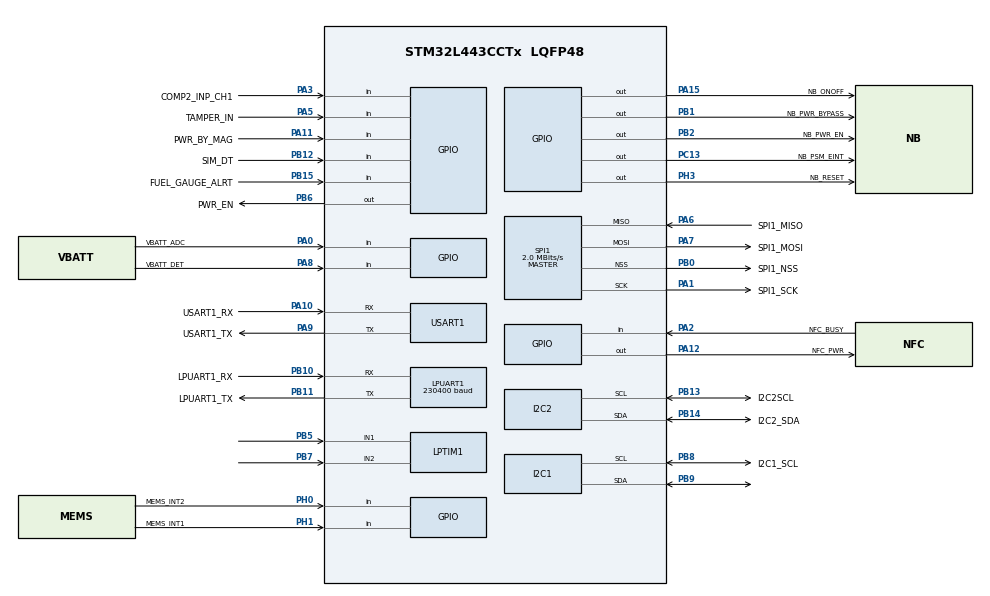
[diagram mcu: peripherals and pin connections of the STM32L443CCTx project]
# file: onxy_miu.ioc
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I2C1.Timing=0x00100D14
I2C2.Timing=0x00100D14
LPUART1.BaudRate=230400
LPUART1.WordLength=UART_WORDLENGTH_8B
Mcu.Family=STM32L4
Mcu.Name=STM32L443CCTx
Mcu.Package=LQFP48
NVIC.LPTIM1_IRQn=true\:0\:0\:false\:false\:true\:true\:true\:true
NVIC.PriorityGroup=NVIC_PRIORITYGROUP_4
NVIC.RTC_Alarm_IRQn=true\:0\:0\:false\:false\:true\:true\:true\:true
NVIC.WWDG_IRQn=true\:0\:0\:false\:false\:true\:true\:true\:true
PA0.GPIO_Label=VBATT_ADC
PA0.Signal=GPIO_Input
PA1.GPIO_Label=SPI1_SCK
PA1.Mode=Full_Duplex_Master
PA1.Signal=SPI1_SCK
PA10.GPIO_Label=USART1_RX
PA10.Mode=Asynchronous
PA10.Signal=USART1_RX
PA11.GPIO_Label=PWR_BY_MAG
PA11.Signal=GPIO_Input
PA12.GPIO_Label=NFC_PWR
PA12.Signal=GPIO_Output
PA13\ (JTMS-SWDIO).Mode=Serial_Wire
PA13\ (JTMS-SWDIO).Signal=SYS_JTMS-SWDIO
PA14\ (JTCK-SWCLK).Mode=Serial_Wire
PA14\ (JTCK-SWCLK).Signal=SYS_JTCK-SWCLK
PA15\ (JTDI).GPIO_Label=NB_ONOFF
PA15\ (JTDI).Signal=GPIO_Output
PA2.GPIO_Label=NFC_BUSY
PA2.Signal=GPIO_Input
PA3.GPIO_Label=COMP2_INP_CH1
PA3.Signal=GPIO_Input
PA5.GPIO_Label=TAMPER_IN
PA5.Signal=GPIO_Input
PA6.GPIO_Label=SPI1_MISO
PA6.Mode=Full_Duplex_Master
PA6.Signal=SPI1_MISO
PA7.GPIO_Label=SPI1_MOSI
PA7.Mode=Full_Duplex_Master
PA7.Signal=SPI1_MOSI
PA8.GPIO_Label=VBATT_DET
PA8.Signal=GPIO_Input
PA9.GPIO_Label=USART1_TX
PA9.Mode=Asynchronous
PA9.Signal=USART1_TX
PB0.GPIO_Label=SPI1_NSS
PB0.Mode=NSS_Signal_Hard_Output
PB0.Signal=SPI1_NSS
PB1.GPIO_Label=NB_PWR_BYPASS
PB1.Signal=GPIO_Output
PB10.GPIO_Label=LPUART1_RX
PB10.Mode=Asynchronous
PB10.Signal=LPUART1_RX
PB11.GPIO_Label=LPUART1_TX
PB11.Mode=Asynchronous
PB11.Signal=LPUART1_TX
PB12.GPIO_Label=SIM_DT
PB12.Signal=GPIO_Input
PB13.GPIO_Label=I2C2SCL
PB13.Mode=I2C
PB13.Signal=I2C2_SCL
PB14.GPIO_Label=I2C2_SDA
PB14.Mode=I2C
PB14.Signal=I2C2_SDA
PB15.GPIO_Label=FUEL_GAUGE_ALRT
PB15.Signal=GPIO_Input
PB2.GPIO_Label=NB_PWR_EN
PB2.Signal=GPIO_Output
PB5.Mode=Encoder_mode_occur1
PB5.Signal=LPTIM1_IN1
PB6.GPIO_Label=PWR_EN
PB6.Signal=GPIO_Output
PB7.Mode=Encoder_mode_occur1
PB7.Signal=LPTIM1_IN2
PB8.GPIO_Label=I2C1_SCL
PB8.Mode=I2C
PB8.Signal=I2C1_SCL
PB9.Mode=I2C
PB9.Signal=I2C1_SDA
PC13.GPIO_Label=NB_PSM_EINT
PC13.Signal=GPIO_Output
PC14-OSC32_IN\ (PC14).Mode=LSE-External-Oscillator
PC14-OSC32_IN\ (PC14).Signal=RCC_OSC32_IN
PC15-OSC32_OUT\ (PC15).Mode=LSE-External-Oscillator
PC15-OSC32_OUT\ (PC15).Signal=RCC_OSC32_OUT
PH0-OSC_IN\ (PH0).GPIO_Label=MEMS_INT2
PH0-OSC_IN\ (PH0).Signal=GPIO_Input
PH1-OSC_OUT\ (PH1).GPIO_Label=MEMS_INT1
PH1-OSC_OUT\ (PH1).Signal=GPIO_Input
PH3-BOOT0.GPIO_Label=NB_RESET
PH3-BOOT0.Signal=GPIO_Output
ProjectManager.HeapSize=0x200
ProjectManager.StackSize=0x400
ProjectManager.TargetToolchain=STM32CubeIDE
RCC.AHBFreq_Value=4000000
RCC.APB1Freq_Value=4000000
RCC.APB1TimFreq_Value=4000000
RCC.APB2Freq_Value=4000000
RCC.APB2TimFreq_Value=4000000
RCC.CortexFreq_Value=4000000
RCC.HCLKFreq_Value=4000000
RCC.HSE_VALUE=8000000
RCC.HSI48_VALUE=48000000
RCC.HSI_VALUE=16000000
RCC.MSI_VALUE=4000000
RCC.RTCClockSelection=RCC_RTCCLKSOURCE_LSE
RCC.SYSCLKFreq_VALUE=4000000
RCC.VCOOutputFreq_Value=32000000
RTC.Alarm-Alarm\ A=RTC_ALARM_A
SPI1.CalculateBaudRate=2.0 MBits/s
SPI1.Direction=SPI_DIRECTION_2LINES
SPI1.Mode=SPI_MODE_MASTER
SPI1.VirtualNSS=VM_NSSHARD
SPI1.VirtualType=VM_MASTER
USART1.VirtualMode-Asynchronous=VM_ASYNC
VP_CRC_VS_CRC.Mode=CRC_Activate
VP_RTC_VS_RTC_Activate.Mode=RTC_Enabled
VP_RTC_VS_RTC_Alarm_A_Intern.Mode=Alarm A
VP_RTC_VS_RTC_Calendar.Mode=RTC_Calendar
VP_WWDG_VS_WWDG.Mode=WWDG_Activate
board=custom

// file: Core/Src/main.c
/* USER CODE BEGIN Header */
/**
  ******************************************************************************
  * @file           : main.c
  * @brief          : Main program body
  ******************************************************************************
  * @attention
  *
  * Copyright (c) 2025 STMicroelectronics.
  * All rights reserved.
  *
  * This software is licensed under terms that can be found in the LICENSE file
  * in the root directory of this software component.
  * If no LICENSE file comes with this software, it is provided AS-IS.
  *
  ******************************************************************************
  */
/* USER CODE END Header */
#include "main.h"
#include "crc.h"
#include "i2c.h"
#include "lptim.h"
#include "usart.h"
#include "rtc.h"
#include "spi.h"
#include "wwdg.h"
#include "gpio.h"

/* USER CODE BEGIN Includes */
#include "app_main.h"
/* USER CODE END Includes */

void SystemClock_Config(void);

/* USER CODE BEGIN 0 */

#if PARTITION == 0
/*name changed so we don't enter here. Partition 0's main is in bootloader.c*/
int MAIN_main(void) {
#else
/* USER CODE END 0 */

int main(void)
{

  /* USER CODE BEGIN 1 */
#endif
  /* USER CODE END 1 */

  /* MCU Configuration--------------------------------------------------------*/

  /* Reset of all peripherals, Initializes the Flash interface and the Systick. */
  HAL_Init();

  /* Configure the system clock */
  SystemClock_Config();

  /* Initialize all configured peripherals */
  MX_GPIO_Init();
  MX_LPTIM1_Init();
  MX_I2C1_Init();
  MX_I2C2_Init();
  MX_LPUART1_UART_Init();
  MX_USART1_UART_Init();
  MX_SPI1_Init();
  MX_RTC_Init();
  MX_WWDG_Init();
  MX_CRC_Init();
  /* USER CODE BEGIN 2 */
  APP_Init();
  /* USER CODE END 2 */

  /* Infinite loop */
  while (1)
  {
    APP_Main();
  }
}

void SystemClock_Config(void)
{
  LL_FLASH_SetLatency(LL_FLASH_LATENCY_0);
  while(LL_FLASH_GetLatency()!= LL_FLASH_LATENCY_0)
  {
  }
  LL_PWR_SetRegulVoltageScaling(LL_PWR_REGU_VOLTAGE_SCALE1);
  while (LL_PWR_IsActiveFlag_VOS() != 0)
  {
  }
  LL_RCC_MSI_Enable();

   /* Wait till MSI is ready */
  while(LL_RCC_MSI_IsReady() != 1)
  {

  }
  LL_RCC_MSI_EnableRangeSelection();
  LL_RCC_MSI_SetRange(LL_RCC_MSIRANGE_6);
  LL_RCC_MSI_SetCalibTrimming(0);
  LL_PWR_EnableBkUpAccess();
  LL_RCC_LSE_SetDriveCapability(LL_RCC_LSEDRIVE_LOW);
  LL_RCC_LSE_Enable();

   /* Wait till LSE is ready */
  while(LL_RCC_LSE_IsReady() != 1)
  {

  }
  LL_RCC_MSI_EnablePLLMode();
  LL_RCC_SetSysClkSource(LL_RCC_SYS_CLKSOURCE_MSI);

   /* Wait till System clock is ready */
  while(LL_RCC_GetSysClkSource() != LL_RCC_SYS_CLKSOURCE_STATUS_MSI)
  {

  }
  LL_RCC_SetAHBPrescaler(LL_RCC_SYSCLK_DIV_1);
  LL_RCC_SetAPB1Prescaler(LL_RCC_APB1_DIV_1);
  LL_RCC_SetAPB2Prescaler(LL_RCC_APB2_DIV_1);
  LL_SetSystemCoreClock(4000000);

   /* Update the time base */
  if (HAL_InitTick (TICK_INT_PRIORITY) != HAL_OK)
  {
    Error_Handler();
  }
}

void Error_Handler(void)
{
  __disable_irq();
  while (1)
  {
  }
}
